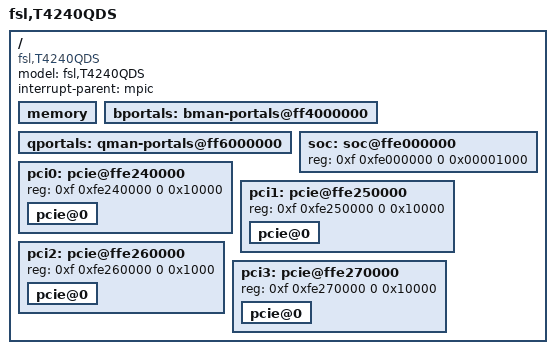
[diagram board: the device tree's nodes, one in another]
/*
 * T4240QDS Device Tree Source
 *
 * Copyright 2012 Freescale Semiconductor Inc.
 *
 * Redistribution and use in source and binary forms, with or without
 * modification, are permitted provided that the following conditions are met:
 *     * Redistributions of source code must retain the above copyright
 *       notice, this list of conditions and the following disclaimer.
 *     * Redistributions in binary form must reproduce the above copyright
 *       notice, this list of conditions and the following disclaimer in the
 *       documentation and/or other materials provided with the distribution.
 *     * Neither the name of Freescale Semiconductor nor the
 *       names of its contributors may be used to endorse or promote products
 *       derived from this software without specific prior written permission.
 *
 *
 * ALTERNATIVELY, this software may be distributed under the terms of the
 * GNU General Public License ("GPL") as published by the Free Software
 * Foundation, either version 2 of that License or (at your option) any
 * later version.
 *
 * THIS SOFTWARE IS PROVIDED BY Freescale Semiconductor ``AS IS'' AND ANY
 * EXPRESS OR IMPLIED WARRANTIES, INCLUDING, BUT NOT LIMITED TO, THE IMPLIED
 * WARRANTIES OF MERCHANTABILITY AND FITNESS FOR A PARTICULAR PURPOSE ARE
 * DISCLAIMED. IN NO EVENT SHALL Freescale Semiconductor BE LIABLE FOR ANY
 * DIRECT, INDIRECT, INCIDENTAL, SPECIAL, EXEMPLARY, OR CONSEQUENTIAL DAMAGES
 * (INCLUDING, BUT NOT LIMITED TO, PROCUREMENT OF SUBSTITUTE GOODS OR SERVICES;
 * LOSS OF USE, DATA, OR PROFITS; OR BUSINESS INTERRUPTION) HOWEVER CAUSED AND
 * ON ANY THEORY OF LIABILITY, WHETHER IN CONTRACT, STRICT LIABILITY, OR TORT
 * (INCLUDING NEGLIGENCE OR OTHERWISE) ARISING IN ANY WAY OUT OF THE USE OF THIS
 * SOFTWARE, EVEN IF ADVISED OF THE POSSIBILITY OF SUCH DAMAGE.
 */

/include/ "fsl/t4240si-pre.dtsi"

/ {
	model = "fsl,T4240QDS";
	compatible = "fsl,T4240QDS";
	#address-cells = <2>;
	#size-cells = <2>;
	interrupt-parent = <&mpic>;

	memory {
		device_type = "memory";
	};

	bportals: bman-portals@ff4000000 {
		ranges = <0x0 0xf 0xf4000000 0x2000000>;
	};

	qportals: qman-portals@ff6000000 {
		ranges = <0x0 0xf 0xf6000000 0x2000000>;
	};


	soc: soc@ffe000000 {
		ranges = <0x00000000 0xf 0xfe000000 0x1000000>;
		reg = <0xf 0xfe000000 0 0x00001000>;
	};

	pci0: pcie@ffe240000 {
		reg = <0xf 0xfe240000 0 0x10000>;
		ranges = <0x02000000 0 0xe0000000 0xc 0x00000000 0x0 0x20000000
			  0x01000000 0 0x00000000 0xf 0xf8000000 0x0 0x00010000>;
		pcie@0 {
			ranges = <0x02000000 0 0xe0000000
				  0x02000000 0 0xe0000000
				  0 0x20000000

				  0x01000000 0 0x00000000
				  0x01000000 0 0x00000000
				  0 0x00010000>;
		};
	};

	pci1: pcie@ffe250000 {
		reg = <0xf 0xfe250000 0 0x10000>;
		ranges = <0x02000000 0x0 0xe0000000 0xc 0x20000000 0x0 0x20000000
			  0x01000000 0x0 0x00000000 0xf 0xf8010000 0x0 0x00010000>;
		pcie@0 {
			ranges = <0x02000000 0 0xe0000000
				  0x02000000 0 0xe0000000
				  0 0x20000000

				  0x01000000 0 0x00000000
				  0x01000000 0 0x00000000
				  0 0x00010000>;
		};
	};

	pci2: pcie@ffe260000 {
		reg = <0xf 0xfe260000 0 0x1000>;
		ranges = <0x02000000 0 0xe0000000 0xc 0x40000000 0 0x20000000
			  0x01000000 0 0x00000000 0xf 0xf8020000 0 0x00010000>;
		pcie@0 {
			ranges = <0x02000000 0 0xe0000000
				  0x02000000 0 0xe0000000
				  0 0x20000000

				  0x01000000 0 0x00000000
				  0x01000000 0 0x00000000
				  0 0x00010000>;
		};
	};

	pci3: pcie@ffe270000 {
		reg = <0xf 0xfe270000 0 0x10000>;
		ranges = <0x02000000 0 0xe0000000 0xc 0x60000000 0 0x20000000
			  0x01000000 0 0x00000000 0xf 0xf8030000 0 0x00010000>;
		pcie@0 {
			ranges = <0x02000000 0 0xe0000000
				  0x02000000 0 0xe0000000
				  0 0x20000000

				  0x01000000 0 0x00000000
				  0x01000000 0 0x00000000
				  0 0x00010000>;
		};
	};
};

/include/ "fsl/t4240si-post.dtsi"
/include/ "fsl/qoriq-dpaa-res3.dtsi"
